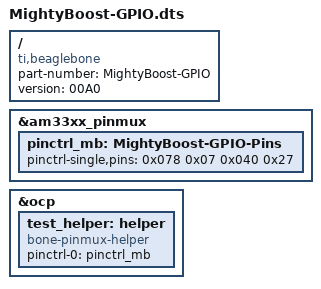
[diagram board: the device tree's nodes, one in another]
/*  
* Copyright (C) 2012 Texas Instruments Incorporated - http://www.ti.com/
*
* This program is free software; you can redistribute it and/or modify
* it under the terms of the GNU General Purpose License Version 2 as
* published by the Free Software Foundation
*
* Original from: github.com/jadonk/validation-scripts/blob/master/test-capemgr/ 
*
* Modified by Lars Toft Jacobsen for LowPowerLab MightyBoost BBB compatability
*/

/dts-v1/;
/plugin/;

/{
       compatible = "ti,beaglebone", "ti,beaglebone-black";
       part-number = "MightyBoost-GPIO";
       version = "00A0";

        fragment@0 {
            target = <&am33xx_pinmux>;
            
            __overlay__ {
                    pinctrl_mb: MightyBoost-GPIO-Pins {
                        pinctrl-single,pins = <

                            0x078 0x07  /* P9_12 60 OUTPUT MODE7 - BootOK signal */
                            0x040 0x27  /* P9_15 48 INPUT  MODE7 pulldown - Shutdown signal */
                                   
                            /* OUTPUT  GPIO(mode7) 0x07 pulldown, 0x17 pullup, 0x?f no pullup/down */
                            /* INPUT   GPIO(mode7) 0x27 pulldown, 0x37 pullup, 0x?f no pullup/down */

                        >;
                    };
            };
        };

        fragment@1 {
            target = <&ocp>;
                __overlay__ {
                    test_helper: helper {
                        compatible = "bone-pinmux-helper";
                        pinctrl-names = "default";
                        pinctrl-0 = <&pinctrl_mb>;
                        status = "okay";
                    };
                };
        };
};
